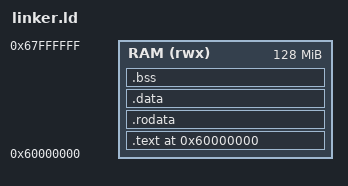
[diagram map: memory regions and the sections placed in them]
/* SPDX-License-Identifier: BSD-3-Clause */

ENTRY(_start)

MEMORY
{
    RAM (rwx) : ORIGIN = 0x60000000, LENGTH = 128M
}

SECTIONS
{
    . = ORIGIN(RAM);

    .text : ALIGN(8) {
        KEEP(*(.text.boot))
        *(.text .text.*)
    } > RAM

    .rodata : ALIGN(8) {
        *(.rodata .rodata.*)
    } > RAM

    .data : ALIGN(8) {
        *(.data .data.*)
    } > RAM

    .bss (NOLOAD) : ALIGN(8) {
        __bss_start = .;
        *(.bss .bss.*)
        *(COMMON)
        __bss_end = .;
    } > RAM

    . = ALIGN(16);
    __stack_top = ORIGIN(RAM) + LENGTH(RAM);
}
